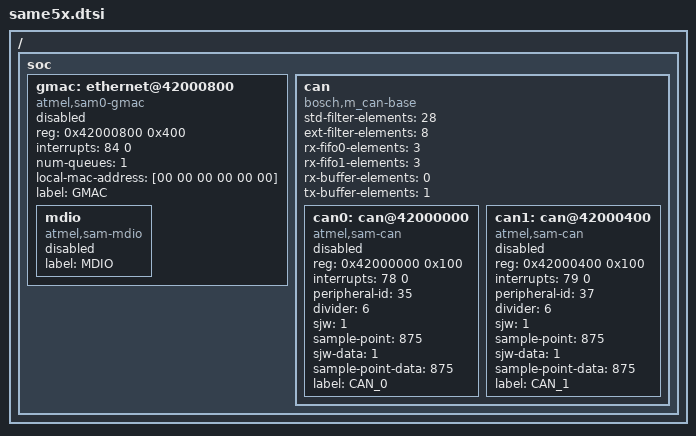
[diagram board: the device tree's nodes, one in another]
/*
 * Copyright (c) 2020 Stephanos Ioannidis <root@stephanos.io>
 *
 * SPDX-License-Identifier: Apache-2.0
 */

#include <atmel/samd5x.dtsi>

/ {
	soc {
		gmac: ethernet@42000800 {
			compatible = "atmel,sam0-gmac";
			reg = <0x42000800 0x400>;
			interrupts = <84 0>;
			interrupt-names = "gmac";
			num-queues = <1>;
			local-mac-address = [00 00 00 00 00 00];
			label = "GMAC";
			status = "disabled";

			mdio: mdio {
				compatible = "atmel,sam-mdio";
				label = "MDIO";
				status = "disabled";
			};
		};

		can {
			compatible = "bosch,m_can-base";
			#address-cells = <1>;
			#size-cells = <1>;
			std-filter-elements = <28>;
			ext-filter-elements = <8>;
			rx-fifo0-elements = <3>;
			rx-fifo1-elements = <3>;
			rx-buffer-elements = <0>;
			tx-buffer-elements = <1>;

			can0: can@42000000 {
				compatible = "atmel,sam-can";
				reg = <0x42000000 0x100>;
				reg-names = "m_can";
				interrupts = <78 0>;
				interrupt-names = "LINE_0";
				peripheral-id = <35>;
				divider = <6>;
				sjw = <1>;
				sample-point = <875>;
				sjw-data = <1>;
				sample-point-data = <875>;
				status = "disabled";
				label = "CAN_0";
			};

			can1: can@42000400 {
				compatible = "atmel,sam-can";
				reg = <0x42000400 0x100>;
				reg-names = "m_can";
				interrupts = <79 0>;
				interrupt-names = "LINE_0";
				peripheral-id = <37>;
				divider = <6>;
				sjw = <1>;
				sample-point = <875>;
				sjw-data = <1>;
				sample-point-data = <875>;
				status = "disabled";
				label = "CAN_1";
			};
		};
	};
};
